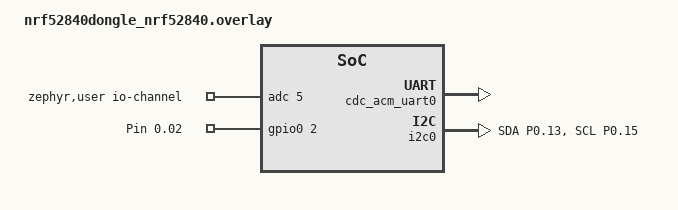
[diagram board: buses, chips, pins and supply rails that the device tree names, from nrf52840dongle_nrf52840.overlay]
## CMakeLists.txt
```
# SPDX-License-Identifier: Apache-2.0

cmake_minimum_required(VERSION 3.20.0)
find_package(Zephyr REQUIRED HINTS $ENV{ZEPHYR_BASE})
project(ot-sensor-lp)

FILE(GLOB app_sources src/*.c)
target_sources(app PRIVATE src/main.c)
target_sources(app PRIVATE src/bme280.c)
```

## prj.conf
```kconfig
# OpenThread config
CONFIG_OPENTHREAD=y
CONFIG_OPENTHREAD_NORDIC_LIBRARY_FTD=n
CONFIG_OPENTHREAD_NORDIC_LIBRARY_MTD=y
CONFIG_OPENTHREAD_MTD=y
CONFIG_OPENTHREAD_MTD_SED=y
CONFIG_OPENTHREAD_COAP=y
CONFIG_OPENTHREAD_COAPS=n
CONFIG_OPENTHREAD_DNS_CLIENT=y
CONFIG_NET_L2_OPENTHREAD=y
CONFIG_NETWORKING=y
CONFIG_NRF_CLOUD_CLIENT_ID_SRC_COMPILE_TIME=n
#CONFIG_OPENTHREAD_POLL_PERIOD=3000

# Network Parameters
CONFIG_OPENTHREAD_MANUAL_START=n
# panid 0xFFFF all networks
CONFIG_OPENTHREAD_PANID=65535
CONFIG_OPENTHREAD_JOINER=y
CONFIG_OPENTHREAD_JOINER_AUTOSTART=y
# JOINER_PSKD Must be a string of all uppercase alphanumeric characters 
# (0-9 and A-Y, excluding I, O, Q, and Z for readability), with a length 
# between 6 and 32 characters.
CONFIG_OPENTHREAD_JOINER_PSKD="START123"
# This variant requires increased system workqueue stack size
CONFIG_SYSTEM_WORKQUEUE_STACK_SIZE=2048

# Network Shell
CONFIG_SHELL=y
CONFIG_OPENTHREAD_SHELL=y
CONFIG_SHELL_ARGC_MAX=26
CONFIG_SHELL_CMD_BUFF_SIZE=416

# Additional Parameters
CONFIG_MBEDTLS_SHA1_C=n
CONFIG_MBEDTLS_HEAP_SIZE=16384
CONFIG_FPU=y

# USB Serial
CONFIG_LOG=y
#CONFIG_LOG_MODE_DEFERRED=n
CONFIG_SERIAL=y
CONFIG_CONSOLE=y
CONFIG_STDOUT_CONSOLE=y
CONFIG_UART_CONSOLE=y
CONFIG_UART_INTERRUPT_DRIVEN=y
CONFIG_UART_LINE_CTRL=y
CONFIG_USB_DEVICE_STACK=y
CONFIG_USB_DEVICE_PRODUCT="OpenThread LowPower"
CONFIG_USB_DRIVER_LOG_LEVEL_ERR=y
CONFIG_USB_DEVICE_LOG_LEVEL_ERR=y
CONFIG_USB_DEVICE_INITIALIZE_AT_BOOT=n

# Sensor
CONFIG_ADC=y
CONFIG_I2C=y
CONFIG_CBPRINTF_COMPLETE=y

# power management
CONFIG_PM=y
CONFIG_PM_DEVICE=y
#CONFIG_NRFX_QSPI=n

# board
#CONFIG_NFCT_PINS_AS_GPIOS=n
#CONFIG_NRFX_CLOCK=n
```

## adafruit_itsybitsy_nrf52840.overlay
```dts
/ {
	chosen {
:			zephyr,i2c = &i2c0;
			zephyr,ieee802154 = &ieee802154;
	};

	// define pins to make them usable in zephyr programs
	pins {
		compatible = "gpio-leds";
		pin05: pin_05 {
				gpios = < &gpio0 5 (GPIO_ACTIVE_HIGH) >;
				label = "Pin 0.05";
		};
	};

	// the alias is used in the zephyr program
	aliases {
			pwr = &pin05; 
			i2c = &i2c0;
	};
}; 

&ieee802154 {
	status = "okay";
};

// Serial over USB
&zephyr_udc0 {
	cdc_acm_uart0: cdc_acm_uart0 {
			compatible = "zephyr,cdc-acm-uart";
			label = "CDC_ACM_0";
	};
};
```

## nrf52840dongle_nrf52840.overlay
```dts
/ {
	chosen {
			zephyr,shell-uart = &cdc_acm_uart0;
			zephyr,console = &cdc_acm_uart0;
			zephyr,i2c = &i2c0;
	};

	zephyr,user {
		io-channels = <&adc 5>;
	};

	// define pins to make them usable in zephyr programs
	pins {
		compatible = "gpio-keys";
		pin02: pin_02 {
				gpios = < &gpio0 2 (GPIO_ACTIVE_HIGH) >;
				label = "Pin 0.02";
		};
	};

	// the alias is used in the zephyr program
	aliases {
			pwr = &pin02; 
			i2c = &i2c0;
	};
}; 

// Serial over USB
&zephyr_udc0 {
	cdc_acm_uart0: cdc_acm_uart0 {
			compatible = "zephyr,cdc-acm-uart";
			label = "CDC_ACM_0";
	};
};

// remapping i2c0 pins to something useful
&pinctrl {
    i2c0_default: i2c0_default {
        group1 {
			psels = <NRF_PSEL(TWIM_SDA, 0, 13)>,
					<NRF_PSEL(TWIM_SCL, 0, 15)>;
			bias-disable;          
        };
    };
	i2c0_sleep: i2c0_sleep {
		group1 {
			psels = <NRF_PSEL(TWIM_SDA, 0, 13)>,
					<NRF_PSEL(TWIM_SCL, 0, 15)>;
			low-power-enable;
		};
	};
};

// activating the i2c0 bus
&i2c0 {
	compatible = "nordic,nrf-twi";
	status = "okay";
	pinctrl-0 = <&i2c0_default>;
	pinctrl-1 = <&i2c0_sleep>;
	pinctrl-names = "default", "sleep";
};
```

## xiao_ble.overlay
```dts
/ {
	chosen {
			//zephyr,shell-uart = &cdc_acm_uart0;
			zephyr,console = &cdc_acm_uart0;
			zephyr,i2c = &i2c0;
	};

	// define pins to make them usable in zephyr programs
	pins {
		compatible = "gpio-leds";
		pin15: pin_15 {
			gpios = < &gpio1 15 (GPIO_ACTIVE_HIGH) >;
			label = "Pin 1.15";
		};
    };

	// the alias is used in the zephyr program
	aliases {
			pwr = &pin15;
            i2c = &i2c1;
            //led1_green = &led1;
            //led1_blue = &led2;
	};
}; 

// Serial over USB
&zephyr_udc0 {
	cdc_acm_uart0: cdc_acm_uart0 {
			compatible = "zephyr,cdc-acm-uart";
			label = "CDC_ACM_0";
	};
};

// remapping i2c0 pins to something useful
&pinctrl {
    // freedom for Pin1.15 !
    spi0_default: spi0_default {
        group1 {
            psels = <NRF_PSEL(SPIM_MOSI, 0, 29)>,
                    <NRF_PSEL(SPIM_MISO, 1, 14)>,
                    <NRF_PSEL(SPIM_SCK,1,13)>;
        };
    };
    spi0_sleep: spi0_sleep {
        group1 {
            psels = <NRF_PSEL(SPIM_MOSI, 0, 29)>,
                    <NRF_PSEL(SPIM_MISO, 1, 14)>,
                    <NRF_PSEL(SPIM_SCK,1,13)>;
        };
    };
};
```

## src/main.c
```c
/*
 * OpenThread Sensor Node
 * Sleepy End Device
 */
#include <zephyr/kernel.h>
#include <zephyr/device.h>
#include <zephyr/devicetree.h>
#include <zephyr/drivers/gpio.h>
#include <zephyr/drivers/adc.h>
#include <string.h>
#include <stdio.h>

#include <openthread/thread.h>
#include <zephyr/pm/pm.h>
#include <zephyr/pm/device.h>
#include <openthread/coap.h>
#include <openthread/dns_client.h>

#define DEBUG
#ifdef DEBUG
	#include <zephyr/drivers/uart.h>
	#include <zephyr/usb/usb_device.h>
	#include <zephyr/logging/log.h>
	LOG_MODULE_REGISTER(ot_sensor, LOG_LEVEL_INF);
#endif

// the devicetree node identifier for the "led1_green" alias
#define LED0_NODE DT_ALIAS(led0)
static const struct gpio_dt_spec led = GPIO_DT_SPEC_GET(LED0_NODE, gpios);

#if DT_NODE_HAS_STATUS(LED0_NODE, okay)
	#define LED0_PIN DT_GPIO_PIN(LED0_NODE, gpios)
#endif

// the devicetree node identifier for our self-defined "pwr" alias.
#define PWR_IO_NODE DT_ALIAS(pwr)
static const struct gpio_dt_spec bme280_power = GPIO_DT_SPEC_GET(PWR_IO_NODE, gpios);

#if DT_NODE_HAS_STATUS(PWR_IO_NODE, okay)
#define PWR_IO_PIN DT_GPIO_PIN(PWR_IO_NODE, gpios)
#endif

// ADC Voodoo
#if !DT_NODE_EXISTS(DT_PATH(zephyr_user)) || \
	!DT_NODE_HAS_PROP(DT_PATH(zephyr_user), io_channels)
#error "No suitable devicetree overlay specified"
#endif

#define DT_SPEC_AND_COMMA(node_id, prop, idx) \
	ADC_DT_SPEC_GET_BY_IDX(node_id, idx),

/* Data of ADC io-channels specified in devicetree. */
static const struct adc_dt_spec adc_channels[] = {
	DT_FOREACH_PROP_ELEM(DT_PATH(zephyr_user), io_channels,
			     DT_SPEC_AND_COMMA)
};

// helper
#define HIGH 1
#define LOW 0
#define SLEEP_TIME 60

// define the BME280 sensor
#include "bme280.h"
struct bme280_result_type bme280_result;

// hostname and ip address of coap server
const char *dnsResolver = "ff03::1"; // mesh-local multicast address
const char *serviceLabel = "coap2mqtt";
const char *serviceName = "_coap._udp.default.service.arpa.";
const char *serviceHostname = "sensordata.default.service.arpa.";
otIp6Address coapServer;
bool resolved = false;

//--------------------------------------------------------------------------
void coap_send(otInstance *ot_instance, char *jsonbuf)
//--------------------------------------------------------------------------
{
	otError ot_error = OT_ERROR_NONE;
	char ip6buf[40];
	otMessage *msg = NULL;
	otMessageInfo msgInfo;
	memset(&msgInfo, 0, sizeof(msgInfo)); // why?
	msgInfo.mPeerPort = OT_DEFAULT_COAP_PORT;
	msgInfo.mPeerAddr = coapServer;

	msg = otCoapNewMessage( ot_instance, NULL);
	otCoapMessageInit(msg, OT_COAP_TYPE_NON_CONFIRMABLE, OT_COAP_CODE_PUT);
	otCoapMessageGenerateToken(msg, OT_COAP_MAX_TOKEN_LENGTH);

	ot_error = otCoapMessageAppendUriPathOptions(msg, "sensordata");
	#ifdef DEBUG
		if (ot_error != OT_ERROR_NONE)
		 { LOG_INF("UriPathOption rc: %s", otThreadErrorToString(ot_error)); }
	#endif

	ot_error = otCoapMessageAppendContentFormatOption(msg, OT_COAP_OPTION_CONTENT_FORMAT_JSON);
	#ifdef DEBUG
		if (ot_error != OT_ERROR_NONE)
		{ LOG_INF("ContentFormatOption rc: %s", otThreadErrorToString(ot_error)); }
	#endif

	ot_error = otCoapMessageSetPayloadMarker(msg);
	#ifdef DEBUG
		if (ot_error != OT_ERROR_NONE)
		{ LOG_INF("SetPayloadMarker rc: %s", otThreadErrorToString(ot_error)); }
	#endif

	ot_error = otMessageAppend(msg, jsonbuf, strlen(jsonbuf));
	#ifdef DEBUG
		if (ot_error != OT_ERROR_NONE)
		{ LOG_INF("MessageAppend rc: %s", otThreadErrorToString(ot_error)); }
	#endif

	ot_error = otCoapSendRequest(ot_instance, msg, &msgInfo, NULL, NULL);
	#ifdef DEBUG
		otIp6AddressToString(&msgInfo.mPeerAddr, ip6buf, 39);
		LOG_INF("COAP endpoint IP: %s, Port: %d", ip6buf, msgInfo.mPeerPort);
		LOG_INF("COAP message rc: %s", otThreadErrorToString(ot_error));
	#endif
	// only call otMessageFree in case of error!
	// otherwise no message is sent and the system hangs!
	if (ot_error != OT_ERROR_NONE) {
		otMessageFree(msg);	
	}
}

//--------------------------------------------------------------------------
static void resolve_callback(otError aError, const otDnsServiceResponse *aResponse, void *aContext)
//--------------------------------------------------------------------------
{
	otError ot_error;
	char *buf[40];
	#ifdef DEBUG
		LOG_INF("DNS resolver callback");
	#endif

	if (aError == OT_ERROR_NONE) {
		ot_error = otDnsServiceResponseGetHostAddress(aResponse, serviceHostname, 0, &coapServer, NULL);
		#ifdef DEBUG
			otIp6AddressToString(&coapServer, buf, 39);
			LOG_INF("service hostname: %s", serviceHostname);
			LOG_INF("service hostname successfully resolved %s", buf);
		#endif
		resolved = true;
	}
	else {
		#ifdef DEBUG
			LOG_ERR("service hostname not resolved!");
		#endif
	}
}

//--------------------------------------------------------------------------
static void resolveCoapServer(otInstance *ot_instance)
//--------------------------------------------------------------------------
{
	otError ot_error;
	char *buf_old[40];
	struct openthread_context *ctx = openthread_get_default_context();

	otDnsQueryConfig *queryConfig = NULL;
	queryConfig = otDnsClientGetDefaultConfig(ot_instance);
	otIp6AddressToString(&queryConfig->mServerSockAddr.mAddress, buf_old, 39);
	#ifdef DEBUG
		LOG_INF("default mDNS server: %s", buf_old);
	#endif

	otIp6AddressFromString(dnsResolver, &queryConfig->mServerSockAddr.mAddress);
	queryConfig->mResponseTimeout = 1000;	
	otDnsClientSetDefaultConfig(ot_instance, queryConfig);
	#ifdef DEBUG
		otIp6AddressToString(&queryConfig->mServerSockAddr.mAddress, dnsResolver, 39);
		LOG_INF("new mDNS server: %s", dnsResolver);
	#endif

	openthread_api_mutex_lock(ctx);
	ot_error = otDnsClientResolveService(ot_instance, serviceLabel, serviceName, resolve_callback, ctx, queryConfig);
	openthread_api_mutex_unlock(ctx);
	#ifdef DEBUG
		LOG_INF("started DNS resolving service rc: %s", otThreadErrorToString(ot_error));
	#endif

	while (resolved == false) {
		k_sleep(K_MSEC(500));
	}
}

//--------------------------------------------------------------------------
void main(void)
//--------------------------------------------------------------------------
{
	char json_buf[100];
	int err;
	
	otExtAddress eui64;
	char eui64_id[25] = "\0";
	char buf[3];

	// USB Voodoo
	#ifdef DEBUG
		err = gpio_pin_configure_dt(&led, GPIO_OUTPUT_HIGH);
		err = gpio_pin_set_dt(&led, HIGH);
		k_sleep(K_MSEC(5000));

		const struct device *usbdev = DEVICE_DT_GET(DT_CHOSEN(zephyr_console));
		uint32_t dtr = 0;

		if (usb_enable(NULL)) {
			LOG_ERR("Failed to enable USB");
			return;
		}

		// wait for serial connection !!! blocking !!!
		while (!dtr) {
			uart_line_ctrl_get(usbdev, UART_LINE_CTRL_DTR, &dtr);
			k_sleep(K_MSEC(100));
		} 
		
		err = gpio_pin_set_dt(&led, LOW);
		LOG_INF("--------------------");
		LOG_INF("--- ot-sensor-lp ---");
		LOG_INF("--------------------");
	#endif

	//-------------------------------------
	// fetch OpenThread instance and EUI64
	//-------------------------------------
	otInstance *ot_instance;
	ot_instance = openthread_get_default_instance();

	otPlatRadioGetIeeeEui64(ot_instance, eui64.m8);

	// convert EUI64 to hex string
	for (uint8_t i=0; i < 8; i++) {
		snprintk(buf, sizeof(buf),"%02X",eui64.m8[i]);
		#ifdef DEBUG
			LOG_INF("byte nr. %d: %s", i, buf);
		#endif
		strcat(eui64_id,buf);
	}
	
	// set TX power to +8dbm
	err = otPlatRadioSetTransmitPower(ot_instance, 8);

	// check if we are connected to a network
	int device_state = otThreadGetDeviceRole(ot_instance);
	while ((device_state == OT_DEVICE_ROLE_DETACHED)
			||(device_state == OT_DEVICE_ROLE_DISABLED)) {
		err = gpio_pin_configure_dt(&led, GPIO_OUTPUT_HIGH);
		err = gpio_pin_set_dt(&led, HIGH);
		k_sleep(K_MSEC(1000));
		device_state = otThreadGetDeviceRole(ot_instance);
	}
	err = gpio_pin_set_dt(&led, LOW);

	// configure i2c power pin
	err = gpio_pin_configure_dt(&bme280_power, GPIO_OUTPUT_HIGH);

	// DNS resolve hostname of COAP Server
	//otError ot_error = otIp6AddressFromString(coapIpv6, &coapServer);
	resolveCoapServer(ot_instance);

	//-------------------------------------
	// Setup ADC
	//-------------------------------------
	int16_t adc_buf;
	int32_t bat_mv;
	struct adc_sequence sequence = {
		.buffer = &adc_buf,
		/* buffer size in bytes, not number of samples */
		.buffer_size = sizeof(adc_buf),
	};

	/* Configure channel prior to sampling. */
	if (!device_is_ready(adc_channels[0].dev)) {
		#ifdef DEBUG
			LOG_ERR("ADC controller device not ready");
		#endif
		return;
	}

	err = adc_channel_setup_dt(&adc_channels[0]);
	if (err < 0) {
		#ifdef DEBUG
			LOG_ERR("Could not setup channel #0 (%d)", err);
		#endif
		return;
	}

	// power down all devices
	pm_device_action_run(i2c_device, PM_DEVICE_ACTION_SUSPEND);
	pm_device_action_run(adc_channels[0].dev, PM_DEVICE_ACTION_SUSPEND);

	//------------------------------------
	// main loop
	//------------------------------------
	while(true) {
		//------------------------------------
		// go to sleep
		//------------------------------------
		#ifdef DEBUG
			LOG_INF("sleep...\n");
		#endif
		//err = gpio_pin_set_dt(&led, LOW);
		k_sleep(K_SECONDS(SLEEP_TIME));
		//err = gpio_pin_set_dt(&led, HIGH);
		#ifdef DEBUG
			LOG_INF("...wake up");
		#endif
		
		//-----------------------------
		// i2c sensor
		//-----------------------------
		// power up i2c sensor
		pm_device_action_run(i2c_device, PM_DEVICE_ACTION_RESUME);
		err = gpio_pin_set_dt(&bme280_power, HIGH);
		k_sleep(K_MSEC(50)); // sensor boot time

		if(!device_is_ready(i2c_device)) {
			#ifdef DEBUG
				LOG_ERR("I2C bus not ready!");
			#endif
			return;
		}

		// init sensor
		err = bme280_chip_init();

		// read chip id
		#ifdef DEBUG
			LOG_INF("I2C Chip ID: 0x%02X", bme280_read_chip_id());
		#endif

		// take measurement
		bme280_result = bme280_read_values();

		// power down BME280 sensor
		err = gpio_pin_set_dt(&bme280_power, LOW);

		// power down i2c bus
		pm_device_action_run(i2c_device, PM_DEVICE_ACTION_SUSPEND);

		//-----------------------------
		// ADC
		//-----------------------------
		// power up ADC
		pm_device_action_run(adc_channels[0].dev, PM_DEVICE_ACTION_RESUME);

		// get battery voltage
		(void)adc_sequence_init_dt(&adc_channels[0], &sequence);
		err = adc_read(adc_channels[0].dev, &sequence);
		bat_mv = adc_buf;
		err = adc_raw_to_millivolts_dt(&adc_channels[0], &bat_mv);

		// power down ADC
		pm_device_action_run(adc_channels[0].dev, PM_DEVICE_ACTION_SUSPEND);

		//------------------------------------
		// construct json message
		//------------------------------------
		snprintk(json_buf, sizeof(json_buf),
			"{ \"id\": \"%s\", \"batt\": %d, \"temp\": %.2f, \"press\": %.2f, \"hum\": %.2f }",
			eui64_id, bat_mv, bme280_result.temp, bme280_result.press, bme280_result.hum);

		#ifdef DEBUG
			LOG_INF("JSON message: %s",json_buf);
		#endif
	
		//------------------------------------
		// send COAP message 
		// -- only if we are connected
		//------------------------------------
		// start COAP
		err = otCoapStart(ot_instance, OT_DEFAULT_COAP_PORT);
		#ifdef DEBUG
			LOG_INF("COAP started, rc: %s", otThreadErrorToString(err));
		#endif

		if(OT_DEVICE_ROLE_CHILD == otThreadGetDeviceRole(ot_instance)) {
			coap_send(ot_instance, json_buf);
		}
		else {
			#ifdef DEBUG
				LOG_ERR("not connected to a network, message not sent");
			#endif
		}

		// stop COAP
		err = otCoapStop(ot_instance);
		#ifdef DEBUG
			LOG_INF("COAP started, rc: %s", otThreadErrorToString(err));
		#endif

		// clear json buffer
		json_buf[0] = "\0";

	};
}
```

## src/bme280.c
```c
/*
*  BME280 driver without device tree
*/
#include <zephyr/device.h>
#include <zephyr/devicetree.h>
#include <zephyr/drivers/i2c.h>
#include <zephyr/sys/byteorder.h>

#define CONFIG_BME280_MODE_FORCED
#define CONFIG_BME280_TEMP_OVER_1X
#define CONFIG_BME280_PRESS_OVER_1X
#define CONFIG_BME280_HUMIDITY_OVER_1X
#define CONFIG_BME280_STANDBY_500MS
#define CONFIG_BME280_FILTER_OFF
#include "bme280.h"

//#define DEBUG
struct bme280_data_type bme280_data;

//------------------------------------
// wait until ready
//------------------------------------
int bme280_wait_until_ready(void)
{
	uint8_t status = 0;
	int ret;

	/* Wait for NVM to copy and measurement to be completed */
	do {
		k_sleep(K_MSEC(3));
		ret = i2c_reg_read_byte(i2c_device, BME280_I2C_ADDRESS, BME280_REG_STATUS, &status);
		if (ret < 0) {
			return ret;
		}
	} while (status & (BME280_STATUS_MEASURING | BME280_STATUS_IM_UPDATE));

	return 0;
}

//------------------------------------
// read chip id 
//------------------------------------
uint8_t bme280_read_chip_id(void) {
    int rc = 0;
    uint8_t read_buf_id[1];

    rc = i2c_reg_read_byte(i2c_device, BME280_I2C_ADDRESS, BME280_REG_ID, read_buf_id);
    if(rc == 0) {
        bme280_data.chip_id = read_buf_id[0];
        return bme280_data.chip_id;
    }
    else {
        return 0;
    }
}

//------------------------------------
// initialize sensor
//------------------------------------
uint8_t bme280_chip_init(void) {
    int rc = 0;
    // soft reset
    rc = i2c_reg_write_byte(i2c_device, BME280_I2C_ADDRESS, BME280_REG_RESET, BME280_CMD_SOFT_RESET);
    if (rc != 0) {
        #ifdef DEBUG
            printk("BME280_CMD_SOFT_RESET err: %d", rc);
        #endif
        return rc;
    }
    rc = bme280_wait_until_ready();
    if (rc != 0) {
        #ifdef DEBUG
            printk("wait until ready err: %d", rc);
        #endif
        return rc;
    }
    // read compensation
    rc = bme280_read_compensation();
    if (rc != 0) {
        #ifdef DEBUG
            printk("read compensation err: %d", rc);
        #endif
        return rc;
    }
    // set oversampling
    rc = i2c_reg_write_byte(i2c_device, BME280_I2C_ADDRESS, BME280_REG_CTRL_HUM, BME280_HUMIDITY_OVER);
    if (rc != 0) {
        #ifdef DEBUG
            printk("BME280_HUMIDITY_OVER err: %d", rc);
        #endif
        return rc;
    }
    rc = i2c_reg_write_byte(i2c_device, BME280_I2C_ADDRESS, BME280_REG_CTRL_MEAS, BME280_CTRL_MEAS_VAL);
    if (rc != 0) {
        #ifdef DEBUG
            printk("BME280_CTRL_MEAS_VAL err: %d", rc);
        #endif
        return rc;
    }
    // more configurations
    rc = i2c_reg_write_byte(i2c_device, BME280_I2C_ADDRESS, BME280_REG_CONFIG, BME280_CONFIG_VAL);
    if (rc != 0) {
        #ifdef DEBUG
            printk("BME280_CONFIG_VAL err: %d", rc);
        #endif
        return rc;
    }
    return 0;
}

//------------------------------------
// read compensation
//------------------------------------
int bme280_read_compensation(void) {
    int rc = 0;
    uint8_t read_buf_temp[6];
    uint8_t read_buf_press[18];
    uint8_t read_buf_hum[7];

    rc = i2c_burst_read(i2c_device, BME280_I2C_ADDRESS, BME280_REG_TEMP_COMP_START, read_buf_temp, sizeof(read_buf_temp));
    if (rc != 0) {
        return rc;
    }
    else {
        bme280_data.dig_t1 = (uint16_t)read_buf_temp[0];
        bme280_data.dig_t1 |= ((uint16_t)read_buf_temp[1])<<8;
        bme280_data.dig_t2 = (uint16_t)read_buf_temp[2];
        bme280_data.dig_t2 |= ((uint16_t)read_buf_temp[3])<<8;
        bme280_data.dig_t3 = (uint16_t)read_buf_temp[4];
        bme280_data.dig_t3 |= ((uint16_t)read_buf_temp[5])<<8;
    }
    
    rc = i2c_burst_read(i2c_device, BME280_I2C_ADDRESS, BME280_REG_PRESS_COMP_START, read_buf_press, sizeof(read_buf_press));
    if (rc != 0) {
        return rc;
    }
    else {
        bme280_data.dig_p1 = (uint16_t)read_buf_press[0];
        bme280_data.dig_p1 |= ((uint16_t)read_buf_press[1])<<8;
        bme280_data.dig_p2 = (uint16_t)read_buf_press[2];
        bme280_data.dig_p2 |= ((uint16_t)read_buf_press[3])<<8;
        bme280_data.dig_p3 = (uint16_t)read_buf_press[4];
        bme280_data.dig_p3 |= ((uint16_t)read_buf_press[5])<<8;
        bme280_data.dig_p4 = (uint16_t)read_buf_press[6];
        bme280_data.dig_p4 |= ((uint16_t)read_buf_press[7])<<8;
        bme280_data.dig_p5 = (uint16_t)read_buf_press[8];
        bme280_data.dig_p5 |= ((uint16_t)read_buf_press[9])<<8;
        bme280_data.dig_p6 = (uint16_t)read_buf_press[10];
        bme280_data.dig_p6 |= ((uint16_t)read_buf_press[11])<<8;
        bme280_data.dig_p7 = (uint16_t)read_buf_press[12];
        bme280_data.dig_p7 |= ((uint16_t)read_buf_press[13])<<8;
        bme280_data.dig_p8 = (uint16_t)read_buf_press[14];
        bme280_data.dig_p8 |= ((uint16_t)read_buf_press[15])<<8;
        bme280_data.dig_p9 = (uint16_t)read_buf_press[16];
        bme280_data.dig_p9 |= ((uint16_t)read_buf_press[17])<<8;
    }

    rc = i2c_reg_read_byte(i2c_device, BME280_I2C_ADDRESS, BME280_REG_HUM_COMP_PART1, &bme280_data.dig_h1);
    if (rc != 0) {
        return rc;
    }

    rc = i2c_burst_read(i2c_device, BME280_I2C_ADDRESS, BME280_REG_HUM_COMP_PART2, read_buf_hum, sizeof(read_buf_hum));
    if (rc != 0) {
        return rc;
    }
    else {
        bme280_data.dig_h2 = (read_buf_hum[1] << 8) | read_buf_hum[0];
        bme280_data.dig_h3 = read_buf_hum[2];
        bme280_data.dig_h4 = (read_buf_hum[3] << 4) | (read_buf_hum[4] & 0x0F);
        bme280_data.dig_h5 = ((read_buf_hum[4] >> 4) & 0x0F) | (read_buf_hum[5] << 4);
        bme280_data.dig_h6 = read_buf_hum[6];
    }
    return rc;
}

/*
 * Compensation code taken from BME280 datasheet, Section 4.2.3
 * "Compensation formula".
 */
void bme280_compensate_temp(void)
{
	int32_t var1, var2;

	var1 = (((bme280_data.ucomp_temp >> 3) - ((int32_t)bme280_data.dig_t1 << 1)) *
		((int32_t)bme280_data.dig_t2)) >> 11;
	var2 = (((((bme280_data.ucomp_temp >> 4) - ((int32_t)bme280_data.dig_t1)) *
		  ((bme280_data.ucomp_temp >> 4) - ((int32_t)bme280_data.dig_t1))) >> 12) *
		((int32_t)bme280_data.dig_t3)) >> 14;
	bme280_data.t_fine = var1 + var2;
	bme280_data.comp_temp = (bme280_data.t_fine * 5 + 128) >> 8;
}

void bme280_compensate_press(void)
{
	int64_t var1, var2, p;

	var1 = ((int64_t)bme280_data.t_fine) - 128000;
	var2 = var1 * var1 * (int64_t)bme280_data.dig_p6;
	var2 = var2 + ((var1 * (int64_t)bme280_data.dig_p5) << 17);
	var2 = var2 + (((int64_t)bme280_data.dig_p4) << 35);
	var1 = ((var1 * var1 * (int64_t)bme280_data.dig_p3) >> 8) +
		((var1 * (int64_t)bme280_data.dig_p2) << 12);
	var1 = (((((int64_t)1) << 47) + var1)) * ((int64_t)bme280_data.dig_p1) >> 33;

	/* Avoid exception caused by division by zero. */
	if (var1 == 0) {
		bme280_data.comp_press = 0U;
		return;
	}

	p = 1048576 - bme280_data.ucomp_press;
	p = (((p << 31) - var2) * 3125) / var1;
	var1 = (((int64_t)bme280_data.dig_p9) * (p >> 13) * (p >> 13)) >> 25;
	var2 = (((int64_t)bme280_data.dig_p8) * p) >> 19;
	p = ((p + var1 + var2) >> 8) + (((int64_t)bme280_data.dig_p7) << 4);

	bme280_data.comp_press = (uint32_t)p;
}

void bme280_compensate_humidity(void)
{
	int32_t h;

	h = (bme280_data.t_fine - ((int32_t)76800));
	h = ((((bme280_data.ucomp_hum << 14) - (((int32_t)bme280_data.dig_h4) << 20) -
		(((int32_t)bme280_data.dig_h5) * h)) + ((int32_t)16384)) >> 15) *
		(((((((h * ((int32_t)bme280_data.dig_h6)) >> 10) * (((h *
		((int32_t)bme280_data.dig_h3)) >> 11) + ((int32_t)32768))) >> 10) +
		((int32_t)2097152)) * ((int32_t)bme280_data.dig_h2) + 8192) >> 14);
	h = (h - (((((h >> 15) * (h >> 15)) >> 7) *
		((int32_t)bme280_data.dig_h1)) >> 4));
	h = (h > 419430400 ? 419430400 : h);

	bme280_data.comp_hum = (uint32_t)(h >> 12);
}

//------------------------------------
// read final values
//------------------------------------
struct bme280_result_type bme280_read_values(void) {
    int rc = 0;
    struct bme280_result_type result;
    uint8_t write_buf[1];
    uint8_t read_meas_buf[8];

    #ifdef CONFIG_BME280_MODE_FORCED
        rc = i2c_reg_write_byte(i2c_device, BME280_I2C_ADDRESS, BME280_REG_CTRL_MEAS, BME280_CTRL_MEAS_VAL);
        if (rc < 0) { 
            #ifdef DEBUG
                printk("forced mode failed! \n"); 
            #endif
        }
    #endif

    rc = bme280_wait_until_ready();
    if (rc != 0) { 
        #ifdef DEBUG
            printk("wait failed! \n"); 
        #endif
    }

    write_buf[0] = BME280_REG_PRESS_MSB;
    rc = i2c_burst_read(i2c_device, BME280_I2C_ADDRESS, BME280_REG_PRESS_MSB, read_meas_buf, 8);
    if (rc != 0) { 
        #ifdef DEBUG
            printk("read meas_buf failed! \n"); 
        #endif
    }
    #ifdef DEBUG
        printk("MEAS buffer: %X, %X, %X, %X, %X, %X, %X, %X\n",
        read_meas_buf[0], read_meas_buf[1], read_meas_buf[2], read_meas_buf[3], 
        read_meas_buf[4], read_meas_buf[5], read_meas_buf[6], read_meas_buf[7]);
    #endif

    bme280_data.ucomp_press = (read_meas_buf[0] << 12) | (read_meas_buf[1] << 4) | (read_meas_buf[2] >> 4);
    bme280_data.ucomp_temp = (read_meas_buf[3] << 12) | (read_meas_buf[4] << 4) | (read_meas_buf[5] >> 4);
    bme280_data.ucomp_hum = (read_meas_buf[6] << 8) | read_meas_buf[7];

    #ifdef DEBUG
        printk("uncompensated - Temp: %X, Press: %X, Hum: %X\n",
                bme280_data.ucomp_temp, bme280_data.ucomp_press, bme280_data.ucomp_hum);
    #endif

    bme280_compensate_temp();
    bme280_compensate_press();
    bme280_compensate_humidity();

    #ifdef DEBUG
        printk("raw result Temp: %X, Press: %X, Hum: %X\n", bme280_data.comp_temp, bme280_data.comp_press, bme280_data.comp_temp);
    #endif
	// bme280_data.comp_temp has a resolution of 0.01 degC.
	// So 5123 equals 51.23 degC.
    result.temp  = bme280_data.comp_temp / 100.0;

    // bme280_data.comp_press has 24 integer bits and 8 fractional.
    // Output value of 24674867 represents
	// 24674867/256 = 96386.2 Pa = 963.862 hPa
    result.press = bme280_data.comp_press / 25600.0;

    // data->comp_humidity has 22 integer bits and 10 fractional.
    // Output value of 47445 represents 
    // 47445/1024 = 46.333 %RH
    result.hum   = bme280_data.comp_hum / 1024.0;

    #ifdef DEBUG
        printk("Results - Temp: %.2f °C, Press: %.2f hPa, Hum: %.2f %%RH\n", result.temp, result.press, result.hum);
    #endif

    return result;
}
```

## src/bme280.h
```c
/*
*  BME280 driver without device tree
*/
#ifndef BME280_H_
#define BME_280_H_

#include <zephyr/device.h>
#include <zephyr/devicetree.h>
#include <zephyr/drivers/i2c.h>
#include <inttypes.h>

// define the BME280 sensor
#define BME280_I2C_ADDRESS              0x76
#define BME280_REG_TEMP_COMP_START	    0x88
#define BME280_REG_PRESS_COMP_START	    0x8E

#define BME280_REG_PRESS_MSB            0xF7
#define BME280_REG_COMP_START           0x88
#define BME280_REG_HUM_COMP_PART1       0xA1
#define BME280_REG_HUM_COMP_PART2       0xE1
#define BME280_REG_ID                   0xD0
#define BME280_REG_CONFIG               0xF5
#define BME280_REG_CTRL_MEAS            0xF4
#define BME280_REG_CTRL_HUM             0xF2
#define BME280_REG_STATUS               0xF3
#define BME280_REG_RESET                0xE0

#define BMP280_CHIP_ID_SAMPLE_1         0x56
#define BMP280_CHIP_ID_SAMPLE_2         0x57
#define BMP280_CHIP_ID_MP               0x58
#define BME280_CHIP_ID                  0x60
#define BME280_MODE_SLEEP               0x00
#define BME280_MODE_FORCED              0x01
#define BME280_MODE_NORMAL              0x03
#define BME280_SPI_3W_DISABLE           0x00
#define BME280_CMD_SOFT_RESET           0xB6
#define BME280_STATUS_MEASURING         0x08
#define BME280_STATUS_IM_UPDATE         0x01

#if defined CONFIG_BME280_MODE_NORMAL
#define BME280_MODE BME280_MODE_NORMAL
#elif defined CONFIG_BME280_MODE_FORCED
#define BME280_MODE BME280_MODE_FORCED
#endif

#if defined CONFIG_BME280_TEMP_OVER_1X
#define BME280_TEMP_OVER                (1 << 5)
#elif defined CONFIG_BME280_TEMP_OVER_2X
#define BME280_TEMP_OVER                (2 << 5)
#elif defined CONFIG_BME280_TEMP_OVER_4X
#define BME280_TEMP_OVER                (3 << 5)
#elif defined CONFIG_BME280_TEMP_OVER_8X
#define BME280_TEMP_OVER                (4 << 5)
#elif defined CONFIG_BME280_TEMP_OVER_16X
#define BME280_TEMP_OVER                (5 << 5)
#endif

#if defined CONFIG_BME280_PRESS_OVER_1X
#define BME280_PRESS_OVER               (1 << 2)
#elif defined CONFIG_BME280_PRESS_OVER_2X
#define BME280_PRESS_OVER               (2 << 2)
#elif defined CONFIG_BME280_PRESS_OVER_4X
#define BME280_PRESS_OVER               (3 << 2)
#elif defined CONFIG_BME280_PRESS_OVER_8X
#define BME280_PRESS_OVER               (4 << 2)
#elif defined CONFIG_BME280_PRESS_OVER_16X
#define BME280_PRESS_OVER               (5 << 2)
#endif

#if defined CONFIG_BME280_HUMIDITY_OVER_1X
#define BME280_HUMIDITY_OVER            1
#elif defined CONFIG_BME280_HUMIDITY_OVER_2X
#define BME280_HUMIDITY_OVER            2
#elif defined CONFIG_BME280_HUMIDITY_OVER_4X
#define BME280_HUMIDITY_OVER            3
#elif defined CONFIG_BME280_HUMIDITY_OVER_8X
#define BME280_HUMIDITY_OVER            4
#elif defined CONFIG_BME280_HUMIDITY_OVER_16X
#define BME280_HUMIDITY_OVER            5
#endif

#if defined CONFIG_BME280_STANDBY_05MS
#define BME280_STANDBY                  0
#elif defined CONFIG_BME280_STANDBY_62MS
#define BME280_STANDBY                  (1 << 5)
#elif defined CONFIG_BME280_STANDBY_125MS
#define BME280_STANDBY                  (2 << 5)
#elif defined CONFIG_BME280_STANDBY_250MS
#define BME280_STANDBY                  (3 << 5)
#elif defined CONFIG_BME280_STANDBY_500MS
#define BME280_STANDBY                  (4 << 5)
#elif defined CONFIG_BME280_STANDBY_1000MS
#define BME280_STANDBY                  (5 << 5)
#elif defined CONFIG_BME280_STANDBY_2000MS
#define BME280_STANDBY                  (6 << 5)
#elif defined CONFIG_BME280_STANDBY_4000MS
#define BME280_STANDBY                  (7 << 5)
#endif

#if defined CONFIG_BME280_FILTER_OFF
#define BME280_FILTER                   0
#elif defined CONFIG_BME280_FILTER_2
#define BME280_FILTER                   (1 << 2)
#elif defined CONFIG_BME280_FILTER_4
#define BME280_FILTER                   (2 << 2)
#elif defined CONFIG_BME280_FILTER_8
#define BME280_FILTER                   (3 << 2)
#elif defined CONFIG_BME280_FILTER_16
#define BME280_FILTER                   (4 << 2)
#endif

#define BME280_CTRL_MEAS_VAL            (BME280_PRESS_OVER | \
					 BME280_TEMP_OVER |  \
					 BME280_MODE)
#define BME280_CONFIG_VAL               (BME280_STANDBY | \
					 BME280_FILTER |  \
					 BME280_SPI_3W_DISABLE)

#define BME280_CTRL_MEAS_OFF_VAL	(BME280_PRESS_OVER | \
					 BME280_TEMP_OVER |  \
					 BME280_MODE_SLEEP)

extern struct bme280_data_type {
	// compensation parameters
	uint16_t	dig_t1;
	int16_t		dig_t2;
	int16_t		dig_t3;
	uint16_t	dig_p1;
	int16_t		dig_p2;
	int16_t		dig_p3;
	int16_t		dig_p4;
	int16_t		dig_p5;
	int16_t		dig_p6;
	int16_t		dig_p7;
	int16_t		dig_p8;
	int16_t		dig_p9;
	uint8_t		dig_h1;
	int16_t		dig_h2;
	uint8_t		dig_h3;
	int16_t		dig_h4;
	int16_t		dig_h5;
	int8_t		dig_h6;

	// uncompensated values
	uint32_t	ucomp_temp;
	uint32_t	ucomp_press;
	uint32_t	ucomp_hum;

	// compensated values
	int32_t		comp_temp;
	uint32_t	comp_press;
	uint32_t	comp_hum;

	// carryover
	int32_t		t_fine;

	uint8_t		chip_id;
};

extern struct bme280_result_type {
	float	temp;
	float	press;
	float	hum;
};

// define the i2c bus
#define I2C_NODE DT_ALIAS(i2c)
static const struct device *i2c_device = DEVICE_DT_GET(I2C_NODE);

//------------------------------------
// initialize sensor
//------------------------------------
uint8_t bme280_chip_init(void);

//------------------------------------
// read chip id
//------------------------------------
uint8_t bme280_read_chip_id(void);

//------------------------------------
// read final values
//------------------------------------
struct bme280_result_type bme280_read_values(void);

#endif
```
